# FM33LG0XX register map
File version: 1.0
CPU: SC000 r1p0, little endian, no MPU, no FPU, 3 interrupt priority bits
Registers are 32-bit, read-write, reset 0x0 unless marked. A register's access mark holds for its fields unless they carry their own. Offsets are from the block's base; [hi:lo] are bit positions.

## CMU — CMU module information
Base 0x40002400
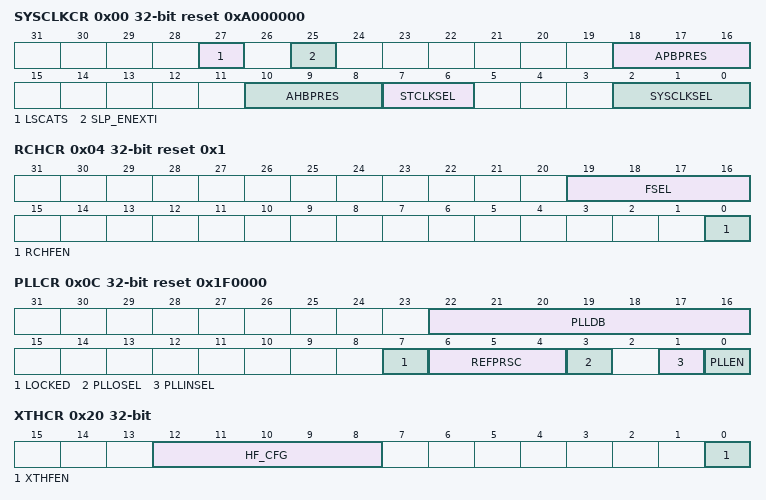
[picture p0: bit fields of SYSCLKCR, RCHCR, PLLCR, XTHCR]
0x00 SYSCLKCR reset 0xA000000 — System Clock Control Register
  [27] LSCATS — LSCATS field description
  [25] SLP_ENEXTI — SLP_ENEXTI field description
  [18:16] APBPRES — APBPRES field description
  [10:8] AHBPRES — AHBPRES field description
  [7:6] STCLKSEL — STCLKSEL field description
  [2:0] SYSCLKSEL — SYSCLKSEL field description
0x04 RCHCR reset 0x1 — RCHF Control Register
  [19:16] FSEL — FSEL field description
  [0] RCHFEN — RCHFEN field description
0x08 RCHTR reset 0x80 — RCHF Trim Register
  [7:0] RCHFTRIM — RCHFTRIM field description
0x0C PLLCR access per field reset 0x1F0000 — PLL Control Register
  [22:16] PLLDB rw — PLLDB field description
  [7] LOCKED ro — LOCKED field description
  [6:4] REFPRSC rw — REFPRSC field description
  [3] PLLOSEL rw — PLLOSEL field description
  [1] PLLINSEL rw — PLLINSEL field description
  [0] PLLEN rw — PLLEN field description
0x10 RCLPCR — RCLP Control Register
  [0] ENB — ENB field description
0x14 RCLPTR reset 0x80 — RCLP Trim Register
  [7:0] RCLP_TRIM — RCLP_TRIM field description
0x1C LSCLKSEL — LSCLK Select Register
  [7:0] LSCLKSEL — LSCLKSEL field description
0x20 XTHCR — XTHF Control Register
  [12:8] HF_CFG — HF_CFG field description
  [0] XTHFEN — XTHFEN field description
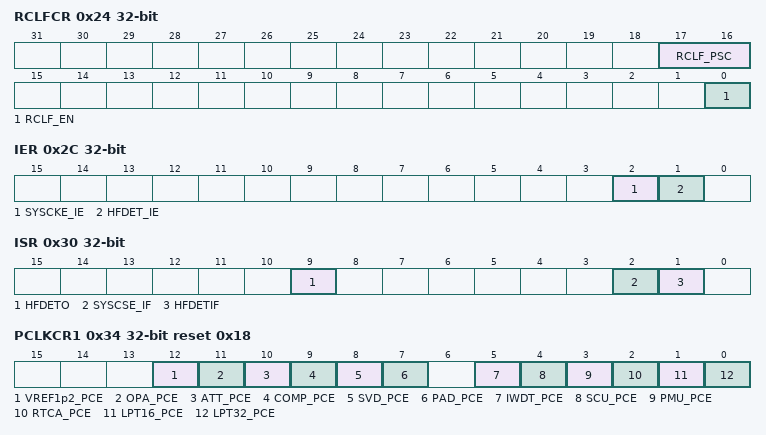
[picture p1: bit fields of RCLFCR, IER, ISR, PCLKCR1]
0x24 RCLFCR — RCLF Control Register
  [17:16] RCLF_PSC — RCLF_PSC field description
  [0] RCLF_EN — RCLF_EN field description
0x28 RCLFTR reset 0x80 — RCLF Trim Register
  [7:0] RCLF_TRIM — RCLF_TRIM field description
0x2C IER — Interrupt Enable Register
  [2] SYSCKE_IE — SYSCKE_IE field description
  [1] HFDET_IE — HFDET_IE field description
0x30 ISR access per field — Interrupt Status Register
  [9] HFDETO ro — HFDETO field description
  [2] SYSCSE_IF rw — SYSCSE_IF field description
  [1] HFDETIF rw — HFDETIF field description
0x34 PCLKCR1 reset 0x18 — Peripheral bus Clock Control Register1
  [12] VREF1p2_PCE — VREF1p2_PCE field description
  [11] OPA_PCE — OPA_PCE field description
  [10] ATT_PCE — ATT_PCE field description
  [9] COMP_PCE — COMP_PCE field description
  [8] SVD_PCE — SVD_PCE field description
  [7] PAD_PCE — PAD_PCE field description
  [5] IWDT_PCE — IWDT_PCE field description
  [4] SCU_PCE — SCU_PCE field description
  [3] PMU_PCE — PMU_PCE field description
  [2] RTCA_PCE — RTCA_PCE field description
  [1] LPT16_PCE — LPT16_PCE field description
  [0] LPT32_PCE — LPT32_PCE field description
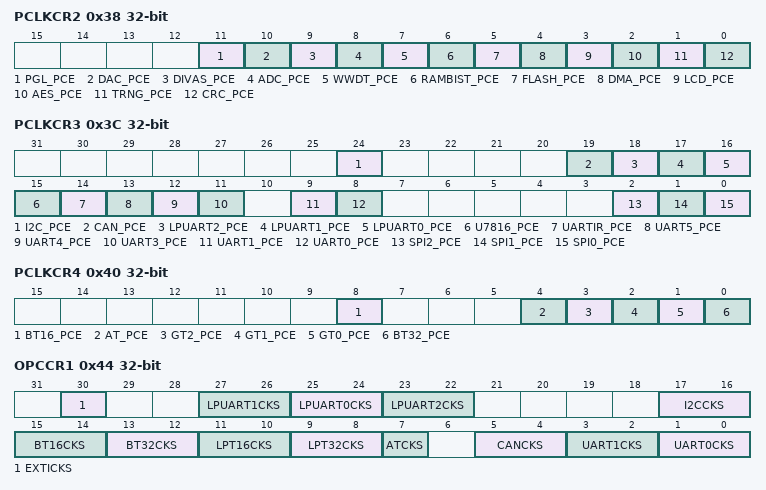
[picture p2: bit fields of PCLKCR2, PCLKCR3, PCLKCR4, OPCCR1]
0x38 PCLKCR2 — Peripheral bus Clock Control Register2
  [11] PGL_PCE — PGL_PCE field description
  [10] DAC_PCE — DAC_PCE field description
  [9] DIVAS_PCE — DIVAS_PCE field description
  [8] ADC_PCE — ADC_PCE field description
  [7] WWDT_PCE — WWDT_PCE field description
  [6] RAMBIST_PCE — RAMBIST_PCE field description
  [5] FLASH_PCE — FLASH_PCE field description
  [4] DMA_PCE — DMA_PCE field description
  [3] LCD_PCE — LCD_PCE field description
  [2] AES_PCE — AES_PCE field description
  [1] TRNG_PCE — TRNG_PCE field description
  [0] CRC_PCE — CRC_PCE field description
0x3C PCLKCR3 — Peripheral bus Clock Control Register3
  [24] I2C_PCE — I2C_PCE field description
  [19] CAN_PCE — CAN_PCE field description
  [18] LPUART2_PCE — LPUART2_PCE field description
  [17] LPUART1_PCE — LPUART1_PCE field description
  [16] LPUART0_PCE — LPUART0_PCE field description
  [15] U7816_PCE — U7816_PCE field description
  [14] UARTIR_PCE — UARTIR_PCE field description
  [13] UART5_PCE — UART5_PCE field description
  [12] UART4_PCE — UART4_PCE field description
  [11] UART3_PCE — UART3_PCE field description
  [9] UART1_PCE — UART1_PCE field description
  [8] UART0_PCE — UART0_PCE field description
  [2] SPI2_PCE — SPI2_PCE field description
  [1] SPI1_PCE — SPI1_PCE field description
  [0] SPI0_PCE — SPI0_PCE field description
0x40 PCLKCR4 — Peripheral bus Clock Control Register4
  [8] BT16_PCE — BT16_PCE field description
  [4] AT_PCE — AT_PCE field description
  [3] GT2_PCE — GT2_PCE field description
  [2] GT1_PCE — GT1_PCE field description
  [1] GT0_PCE — GT0_PCE field description
  [0] BT32_PCE — BT32_PCE field description
0x44 OPCCR1 — Peripheral Clock Config Register1
  [30] EXTICKS — EXTICKS field description
  [27:26] LPUART1CKS — LPUART1CKS field description
  [25:24] LPUART0CKS — LPUART0CKS field description
  [23:22] LPUART2CKS — LPUART2CKS field description
  [17:16] I2CCKS — I2CCKS field description
  [15:14] BT16CKS — BT16CKS field description
  [13:12] BT32CKS — BT32CKS field description
  [11:10] LPT16CKS — LPT16CKS field description
  [9:8] LPT32CKS — LPT32CKS field description
  [7] ATCKS — ATCKS field description
  [5:4] CANCKS — CANCKS field description
  [3:2] UART1CKS — UART1CKS field description
  [1:0] UART0CKS — UART0CKS field description
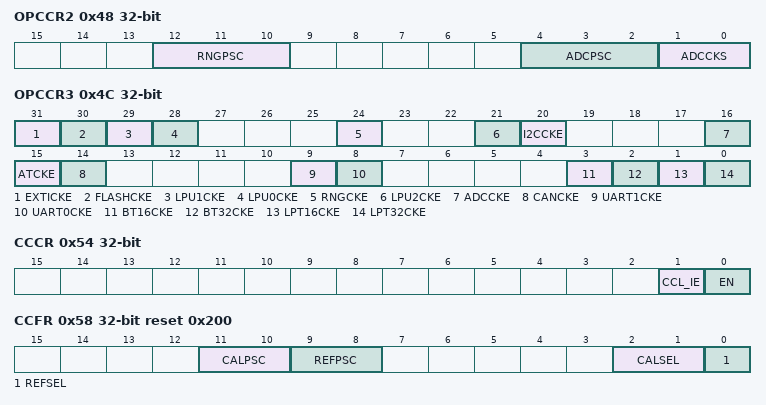
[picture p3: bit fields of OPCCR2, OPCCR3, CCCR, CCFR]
0x48 OPCCR2 — Peripheral Clock Config Register 2
  [12:10] RNGPSC — RNGPSC field description
  [4:2] ADCPSC — ADCPSC field description
  [1:0] ADCCKS — ADCCKS field description
0x4C OPCCR3 — Peripheral Clock Config Register 3
  [31] EXTICKE — EXTICKE field description
  [30] FLASHCKE — FLASHCKE field description
  [29] LPU1CKE — LPU1CKE field description
  [28] LPU0CKE — LPU0CKE field description
  [24] RNGCKE — RNGCKE field description
  [21] LPU2CKE — LPU2CKE field description
  [20] I2CCKE — I2CCKE field description
  [16] ADCCKE — ADCCKE field description
  [15] ATCKE — ATCKE field description
  [14] CANCKE — CANCKE field description
  [9] UART1CKE — UART1CKE field description
  [8] UART0CKE — UART0CKE field description
  [3] BT16CKE — BT16CKE field description
  [2] BT32CKE — BT32CKE field description
  [1] LPT16CKE — LPT16CKE field description
  [0] LPT32CKE — LPT32CKE field description
0x50 AHBMCR — AHB Master Control Register
  [0] MPRIL — MPRIL field description
0x54 CCCR — Clock Calibration Control Register
  [1] CCL_IE — CCL_IE field description
  [0] EN — EN field description
0x58 CCFR reset 0x200 — Clock Calibration Config Register
  [11:10] CALPSC — CALPSC field description
  [9:8] REFPSC — REFPSC field description
  [2:1] CALSEL — CALSEL field description
  [0] REFSEL — REFSEL field description
0x5C CCNR ro — Clock Calibration Counter Register
  [15:0] CCL_CNT — CCL_CNT field description
0x60 CCISR — Clock Calibration Interrupt Status Register
  [0] CCL_IF — CCL_IF field description
